# MSP430FR2433 register map
Vendor: msp430gen; File version: v0.4.0-29-g702f6f3-dirty
Registers are 16-bit, read-write, reset 0x0 unless marked. A register's access mark holds for its fields unless they carry their own. Offsets are from the block's base; [hi:lo] are bit positions; lines under a group give offsets from that group; {n}, {i} and the like mark numbered series; 'fields as' and 'values as' point back to an identical list.

## TA3
Base 0x00000440
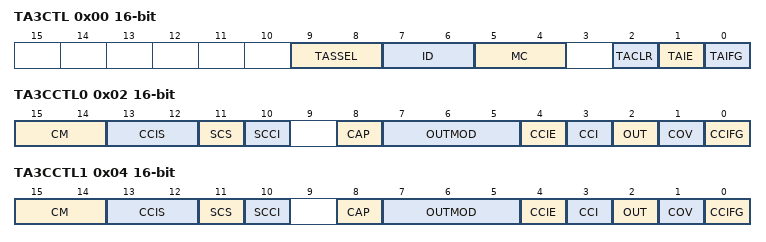
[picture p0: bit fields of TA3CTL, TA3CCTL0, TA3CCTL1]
0x00 TA3CTL — Timer3_A2 Control
  [9:8] TASSEL — Timer A clock source select 1
    0=TACLK (TAxCLK); 1=ACLK; 2=SMCLK; 3=INCLK
  [7:6] ID — Timer A clock input divider 1
    0=/1; 1=/2; 2=/4; 3=/8
  [5:4] MC — Timer A mode control 1
    0=STOP (Stop mode: Timer is halted); 1=UP (Up mode: Timer counts up to TAxCCR0); 2=CONTINUOUS (Continuous mode: Timer counts up to 0FFFFh); 3=UPDOWN (Up/down mode: Timer counts up to TAxCCR0 then down to 0000h)
  [2] TACLR — Timer A counter clear
  [1] TAIE — Timer A counter interrupt enable
  [0] TAIFG — Timer A counter interrupt flag
0x02 TA3CCTL0 — Timer3_A2 Capture/Compare Control 0
  [15:14] CM — Capture mode 1
    0=NONE (No capture); 1=RISING (Capture on rising edge); 2=FALLING (Capture on falling edge); 3=BOTH (Capture on both rising and falling edges)
  [13:12] CCIS — Capture input select 1
    0=CCIA (CCIxA); 1=CCIB (CCIxB); 2=GND; 3=VCC
  [11] SCS — Capture synchronize
  [10] SCCI — Latched capture signal (read)
  [8] CAP — Capture mode: 1 /Compare mode : 0
  [7:5] OUTMOD — Output mode 2
    0=PWM output mode: 0 - output only; 1=PWM output mode: 1 - set; 2=PWM output mode: 2 - PWM toggle/reset; 3=PWM output mode: 3 - PWM set/reset; 4=PWM output mode: 4 - toggle; 5=PWM output mode: 5 - Reset; 6=PWM output mode: 6 - PWM toggle/set; 7=PWM output mode: 7 - PWM reset/set
  [4] CCIE — Capture/compare interrupt enable
  [3] CCI — Capture input signal (read)
  [2] OUT — PWM Output signal if output mode 0
  [1] COV — Capture/compare overflow flag
  [0] CCIFG — Capture/compare interrupt flag
0x04 TA3CCTL1 — Timer3_A2 Capture/Compare Control 1
  fields as TA3CCTL0
0x10 TA3R — Timer3_A2
0x12 TA3CCR0 — Timer3_A2 Capture/Compare 0
0x14 TA3CCR1 — Timer3_A2 Capture/Compare 1
0x20 TA3EX0 — Timer3_A2 Expansion Register 0
  [2:0] TAIDEX — Timer A Input divider expansion Bit: 0
    {v}=/{v+1} (Divide by {v+1}) (v=0..7)
0x2E TA3IV — Timer3_A2 Interrupt Vector Word
  [15:0] TAIV ro — Timer_A interrupt vector value
    0=NONE (No interrupt pending); 2=TACCR1 (Interrupt Source: Capture/compare 1; Interrupt Flag: TAxCCR1 CCIFG; Interrupt Priority: Highest); 4=TACCR2 (Interrupt Source: Capture/compare 2; Interrupt Flag: TAxCCR2 CCIFG); 6=TACCR3 (Interrupt Source: Capture/compare 3; Interrupt Flag: TAxCCR3 CCIFG); 8=TACCR4 (Interrupt Source: Capture/compare 4; Interrupt Flag: TAxCCR4 CCIFG); 10=TACCR5 (Interrupt Source: Capture/compare 5; Interrupt Flag: TAxCCR5 CCIFG); 12=TACCR6 (Interrupt Source: Capture/compare 6; Interrupt Flag: TAxCCR6 CCIFG); 14=TAIFG (Interrupt Source: Timer overflow; Interrupt Flag: TAxCTL TAIFG; Interrupt Priority: Lowest)

## MPY32
Base 0x000004C0
0x00 MPY — Multiply Unsigned/Operand 1
0x02 MPYS — Multiply Signed/Operand 1
0x04 MAC — Multiply Unsigned and Accumulate/Operand 1
0x06 MACS — Multiply Signed and Accumulate/Operand 1
0x08 OP2 — Operand 2
0x0A RESLO — Result Low Word
0x0C RESHI — Result High Word
0x0E SUMEXT — Sum Extend
0x10 MPY32L — 32-bit operand 1 - multiply - low word
0x12 MPY32H — 32-bit operand 1 - multiply - high word
0x14 MPYS32L — 32-bit operand 1 - signed multiply - low word
0x16 MPYS32H — 32-bit operand 1 - signed multiply - high word
0x18 MAC32L — 32-bit operand 1 - multiply accumulate - low word
0x1A MAC32H — 32-bit operand 1 - multiply accumulate - high word
0x1C MACS32L — 32-bit operand 1 - signed multiply accumulate - low word
0x1E MACS32H — 32-bit operand 1 - signed multiply accumulate - high word
0x20 OP2L — 32-bit operand 2 - low word
0x22 OP2H — 32-bit operand 2 - high word
0x24 RES0 — 32x32-bit result 0 - least significant word
0x26 RES1 — 32x32-bit result 1
0x28 RES2 — 32x32-bit result 2
0x2A RES3 — 32x32-bit result 3 - most significant word
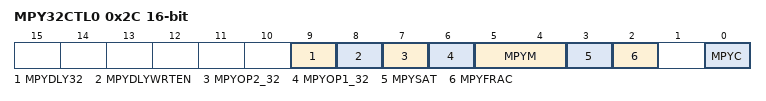
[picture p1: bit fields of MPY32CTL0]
0x2C MPY32CTL0 — MPY32 Control Register 0
  [9] MPYDLY32 — Delayed write mode
  [8] MPYDLYWRTEN — Delayed write enable
  [7] MPYOP2_32 — Bit-width of operand 2 0:16Bit / 1:32Bit
  [6] MPYOP1_32 — Bit-width of operand 1 0:16Bit / 1:32Bit
  [5:4] MPYM — Multiplier mode Bit:0
    0=MPY (MPY Multiply); 1=MPYS (MPYS Signed multiply); 2=MAC (MAC Multiply accumulate); 3=MACS (MACS Signed multiply accumulate)
  [3] MPYSAT — Saturation mode
  [2] MPYFRAC — Fractional mode
  [0] MPYC — Carry of the multiplier

## BAKMEM
Base 0x00000660
{0x0+2i} BAKMEM{i} (i=0..15) — Battery Backup Memory {i}

## TLV — Device descriptors (TLV)
Base 0x00001A00
0x00 INFO_LENGTH 8-bit ro
0x01 CRC_LENGTH 8-bit ro
0x02 CRC_VALUE ro — CRC value of the descriptors from 1A04h to 1AF5h (CRC-CCITT)
0x04 DEVICE_ID ro
{0x4+i} CRC_DATA[{i}] (i=0..241) 8-bit ro — Bytes 1A04h to 1AF5h, the range the CRC value covers
0x06 HW_REVISION 8-bit ro — Hardware revision
0x07 FW_REVISION 8-bit ro — Firmware revision
0x08 DIE_RECORD_TAG 8-bit ro
0x09 DIE_RECORD_LENGTH 8-bit ro
0x0A LOT_WAFER_ID 32-bit ro
0x0E DIE_X_POSITION ro
0x10 DIE_Y_POSITION ro
0x12 TEST_RESULT ro
0x14 ADC_CAL_TAG 8-bit ro — ADC calibration tag
0x15 ADC_CAL_LENGTH 8-bit ro — ADC calibration length
0x16 ADC_GAIN_FACTOR ro
0x18 ADC_OFFSET ro
{0x1A+4i} ADC_TEMP_CAL[{i}] (i=0..0) group — Temperature sensor calibration with the 1.5 V reference
  0x00 TEMP_30C ro — Temperature sensor ADC result at 30 degrees C
  0x02 TEMP_HIGH ro — Temperature sensor ADC result at 85 degrees C
0x1E REF_CAL_TAG 8-bit ro — REF calibration tag
0x1F REF_CAL_LENGTH 8-bit ro — REF calibration length
{0x20+2i} REF_FACTOR[{i}] (i=0..0) ro — Factor of the 1.5 V reference
0x22 DCO_TAP_16MHZ ro — DCO tap setting for 16 MHz
